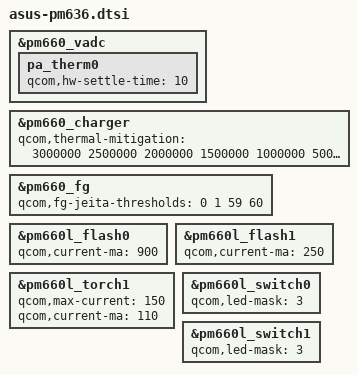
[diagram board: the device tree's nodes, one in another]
// SPDX-License-Identifier: GPL-2.0
// Copyright (C) 2021 Atom-X-Devs < https://www.github.com/Atom-X-Devs >

#include "asus-pm660.dtsi"

// asus pm660.dtsi specific diff
&pm660_vadc {
	pa_therm0 {
		qcom,hw-settle-time = <10>; /* 10 ms */
	};
};

&pm660_charger {
	/delete-property/ ADC_SW_EN-gpios59;
	/delete-property/ ADCPWREN_PMI_GP1-gpios34;
	qcom,thermal-mitigation = <3000000 2500000 2000000 1500000 1000000 500000>;
};

&pm660_fg {
	qcom,fg-jeita-thresholds = <0 1 59 60>;
};

// asus pm660l.dtsi diff
&pm660l_flash0 {
	qcom,current-ma = <900>;
};

&pm660l_flash1 {
	qcom,current-ma = <250>;
};

&pm660l_torch1 {
	qcom,max-current = <150>;
	qcom,current-ma = <110>;
};

&pm660l_switch0 {
	qcom,led-mask = <3>;
};

&pm660l_switch1 {
	qcom,led-mask = <3>;
};
